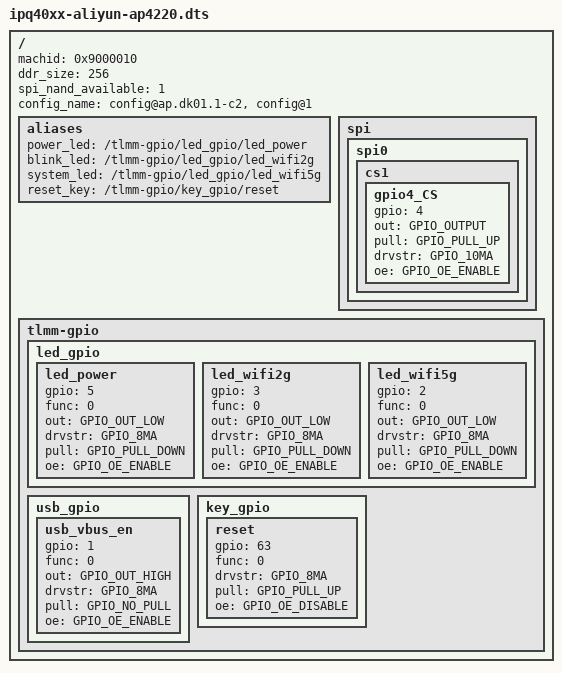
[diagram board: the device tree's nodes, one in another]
/*
 * Copyright (c) 2016, The Linux Foundation. All rights reserved.
 *
 * This program is free software; you can redistribute it and/or modify
 * it under the terms of the GNU General Public License version 2 and
 * only version 2 as published by the Free Software Foundation.
 *
 * This program is distributed in the hope that it will be useful,
 * but WITHOUT ANY WARRANTY; without even the implied warranty of
 * MERCHANTABILITY or FITNESS FOR A PARTICULAR PURPOSE.  See the
 * GNU General Public License for more details.
 */

/dts-v1/;
#include "ipq40xx-dk01.dtsi"

/ {
	machid = <0x9000010>;
	ddr_size = <256>;
	spi_nand_available = <1>;
	config_name = "config@ap.dk01.1-c2", "config@1";

	aliases {
		power_led = "/tlmm-gpio/led_gpio/led_power";
		blink_led = "/tlmm-gpio/led_gpio/led_wifi2g";
		system_led = "/tlmm-gpio/led_gpio/led_wifi5g";
		reset_key = "/tlmm-gpio/key_gpio/reset";
	};

	spi {
		spi0 {
			cs1 {
				gpio4_CS {
					gpio = <4>;
					out = <GPIO_OUTPUT>;
					pull = <GPIO_PULL_UP>;
					drvstr = <GPIO_10MA>;
					oe = <GPIO_OE_ENABLE>;
				};
			};
		};
	};

	tlmm-gpio {
		led_gpio {
			led_power {
				gpio = <5>;
				func = <0>;
				out = <GPIO_OUT_LOW>;
				drvstr = <GPIO_8MA>;
				pull = <GPIO_PULL_DOWN>;
				oe = <GPIO_OE_ENABLE>;
			};
			led_wifi2g {
				gpio = <3>;
				func = <0>;
				out = <GPIO_OUT_LOW>;
				drvstr = <GPIO_8MA>;
				pull = <GPIO_PULL_DOWN>;
				oe = <GPIO_OE_ENABLE>;
			};
			led_wifi5g {
				gpio = <2>;
				func = <0>;
				out = <GPIO_OUT_LOW>;
				drvstr = <GPIO_8MA>;
				pull = <GPIO_PULL_DOWN>;
				oe = <GPIO_OE_ENABLE>;
			};
		};
		usb_gpio {
			usb_vbus_en {
				gpio = <1>;
				func = <0>;
				out = <GPIO_OUT_HIGH>;
				drvstr = <GPIO_8MA>;
				pull = <GPIO_NO_PULL>;
				oe = <GPIO_OE_ENABLE>;
			};
		};
		key_gpio {
			reset {
				gpio = <63>;
				func = <0>;
				drvstr = <GPIO_8MA>;
				pull = <GPIO_PULL_UP>;
				oe = <GPIO_OE_DISABLE>;
			};
		};
	};
};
